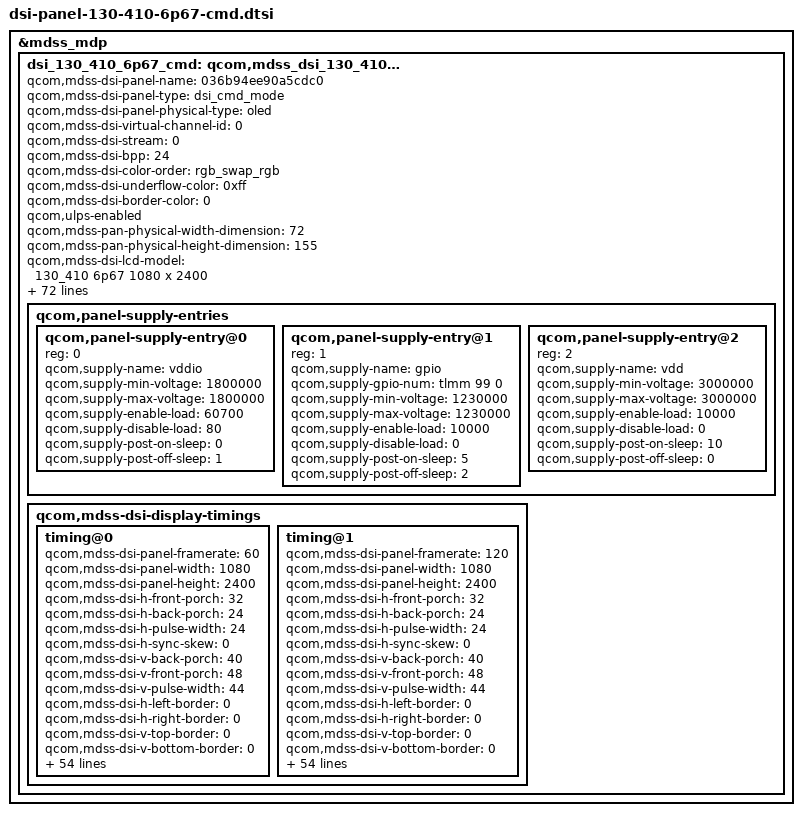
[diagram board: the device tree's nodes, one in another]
&mdss_mdp {
	dsi_130_410_6p67_cmd: qcom,mdss_dsi_130_410_6p67_cmd {
		qcom,mdss-dsi-panel-name = "036b94ee90a5cdc0";
		qcom,mdss-dsi-panel-type = "dsi_cmd_mode";
		qcom,mdss-dsi-panel-physical-type = "oled";
		qcom,mdss-dsi-virtual-channel-id = <0>;
		qcom,mdss-dsi-stream = <0>;
		qcom,mdss-dsi-bpp = <24>;
		qcom,mdss-dsi-color-order = "rgb_swap_rgb";
		qcom,mdss-dsi-underflow-color = <0xff>;
		qcom,mdss-dsi-border-color = <0>;
		qcom,ulps-enabled;
		qcom,mdss-pan-physical-width-dimension = <72>;
		qcom,mdss-pan-physical-height-dimension = <155>;
		qcom,mdss-dsi-lcd-model = "130_410 6p67 1080 x 2400";

		/* mipi dsi setting */
		qcom,dsi-ctrl-num = <0>;
		qcom,dsi-phy-num = <0>;
		qcom,dsi-sec-ctrl-num = <1>;
		qcom,dsi-sec-phy-num = <1>;
		qcom,mdss-dsi-traffic-mode = "non_burst_sync_event";
		qcom,mdss-dsi-lane-map = "lane_map_0123";
		qcom,mdss-dsi-bllp-eof-power-mode;
		qcom,mdss-dsi-bllp-power-mode;
		qcom,mdss-dsi-lane-0-state;
		qcom,mdss-dsi-lane-1-state;
		qcom,mdss-dsi-lane-2-state;
		qcom,mdss-dsi-lane-3-state;
		qcom,mdss-dsi-dma-trigger = "trigger_sw";
		qcom,mdss-dsi-mdp-trigger = "none";
		qcom,dsi-select-clocks = "mux_byte_clk0", "mux_pixel_clk0";
		qcom,dsi-select-sec-clocks = "mux_byte_clk1", "mux_pixel_clk1";

		/* TE setting */
		qcom,mdss-dsi-te-pin-select = <1>;
		qcom,mdss-dsi-wr-mem-start = <0x2c>;
		qcom,mdss-dsi-wr-mem-continue = <0x3c>;
		qcom,mdss-dsi-te-dcs-command = <1>;
		qcom,mdss-dsi-te-check-enable;
		qcom,mdss-dsi-te-using-te-pin;

		/* hdr setting */
		qcom,mdss-dsi-panel-hdr-enabled;
		qcom,mdss-dsi-panel-hdr-color-primaries = <14500 15500 32000
			17000 15500 30000 8000 3000>;
		qcom,mdss-dsi-panel-peak-brightness = <4200000>;
		qcom,mdss-dsi-panel-blackness-level = <3230>;

		/* hbm enable */
		qcom,mdss-dsi-panel-hbm-enabled;
		/* hbm delay threshold */
		qcom,mdss-dsi-hbm-left-delaythr = <10000>;
		qcom,mdss-dsi-hbm-right-delaythr = <11500>;

		/* gpio setting */
		qcom,dsi-panel-gpio-address = <0x0F100000 0x1000>;
		qcom,dsi-panel-gpio-pins = <44 99>;
		qcom,dsi-panel-gpio-names = "reset-gpio", "vdd-gpio";

		/* esd check setting */
		qcom,mdss-dsi-panel-status-check-mode = "reg_read";
		qcom,mdss-dsi-panel-status-command = [
			15 01 00 00 01 00 02 FE 00
			06 01 00 01 00 00 01 0A
		];
		qcom,mdss-dsi-panel-status-command-state = "dsi_lp_mode";
		qcom,mdss-dsi-panel-status-value = <0x00 0x9c>;
		qcom,mdss-dsi-panel-status-read-length = <1 1>;
		qcom,esd-check-enabled;

		/* pcd detect*/
		qcom,mdss-dsi-panel-lcd-check-pcd-support;
		qcom,mdss-dsi-panel-lcd-pcd_value_compare_mode = <0>;
		qcom,mdss-dsi-panel-lcd-pcd_mask = <0xff>;
		qcom,mdss-dsi-panel-lcd-pcd_det_num = <1>;
		qcom,mdss-dsi-panel-lcd-check-pcd-expect_vals = <0xFF>;

		/* check reg */
		qcom,mdss-dsi-panel-lcd-check-reg-enabled;
		qcom,mdss-dsi-panel-lcd-check-reg-expect_vals = <0x9c>;

		/* oem info */
		qcom,mdss-dsi-panel-oem-info-enabled;
		qcom,mdss-dsi-panel-oem-2d-barcode-enabled;
		qcom,mdss-dsi-panel-oem-sn-enabled;

		/* backlight setting */
		qcom,mdss-dsi-bl-pmic-control-type = "bl_ctrl_dcs";
		qcom,mdss-dsi-bl-min-level = <3>;
		qcom,mdss-dsi-bl-max-level = <4095>;
		qcom,mdss-brightness-max-level = <4095>;
		qcom,mdss-dsi-bl-inverted-dbv;
		qcom,mdss-dsi-bl-max-nit = <1000>;

		/* dfps setting */
		qcom,dsi-fps-list = <60 120>;

		/* skip normal backlight set when on aod lp1 scene */
		qcom,skip-normal-bl-set-on-aod-enabled;

		/* power on/off timing setting */
		qcom,platform-reset-gpio = <&tlmm 44 0>;
		qcom,mdss-dsi-reset-sequence = <1 1>, <0 1>, <1 50>;
		qcom,mdss-dsi-reset-pre-off-sleep = <2>;
		qcom,mdss-dsi-panel-reset-in-lp11;
		qcom,panel-supply-entries {
			qcom,panel-supply-entry@0 {
				reg = <0>;
				qcom,supply-name = "vddio";
				qcom,supply-min-voltage = <1800000>;
				qcom,supply-max-voltage = <1800000>;
				qcom,supply-enable-load = <60700>;
				qcom,supply-disable-load = <80>;
				qcom,supply-post-on-sleep = <0>;
				qcom,supply-post-off-sleep = <1>;
			};
			qcom,panel-supply-entry@1 {
				reg = <1>;
				qcom,supply-name = "gpio";
				qcom,supply-gpio-num = <&tlmm 99 0>;
				qcom,supply-min-voltage = <1230000>;
				qcom,supply-max-voltage = <1230000>;
				qcom,supply-enable-load = <10000>;
				qcom,supply-disable-load = <0>;
				qcom,supply-post-on-sleep = <5>;
				qcom,supply-post-off-sleep = <2>;
                        };
			qcom,panel-supply-entry@2 {
				reg = <2>;
				qcom,supply-name = "vdd";
				qcom,supply-min-voltage = <3000000>;
				qcom,supply-max-voltage = <3000000>;
				qcom,supply-enable-load = <10000>;
				qcom,supply-disable-load = <0>;
				qcom,supply-post-on-sleep = <10>;
				qcom,supply-post-off-sleep = <0>;
			};
		};
		/* display timing0 */
		qcom,mdss-dsi-display-timings {
			timing@0 {
				qcom,mdss-dsi-panel-framerate = <60>;
				qcom,mdss-dsi-panel-width = <1080>;
				qcom,mdss-dsi-panel-height = <2400>;
				qcom,mdss-dsi-h-front-porch = <32>;
				qcom,mdss-dsi-h-back-porch = <24>;
				qcom,mdss-dsi-h-pulse-width = <24>;
				qcom,mdss-dsi-h-sync-skew = <0>;
				qcom,mdss-dsi-v-back-porch = <40>;
				qcom,mdss-dsi-v-front-porch = <48>;
				qcom,mdss-dsi-v-pulse-width = <44>;
				qcom,mdss-dsi-h-left-border = <0>;
				qcom,mdss-dsi-h-right-border = <0>;
				qcom,mdss-dsi-v-top-border = <0>;
				qcom,mdss-dsi-v-bottom-border = <0>;
				qcom,mdss-dsi-panel-jitter = <0x4 0x1>;

				qcom,mdss-dsi-on-command = [
					15 01 00 00 00 00 02 FE D2
					15 01 00 00 00 00 02 4F 08
					15 01 00 00 00 00 02 50 12
					15 01 00 00 00 00 02 51 aB
					15 01 00 00 00 00 02 52 30
					15 01 00 00 00 00 02 53 09
					15 01 00 00 00 00 02 54 60
					15 01 00 00 00 00 02 55 04
					15 01 00 00 00 00 02 56 38
					15 01 00 00 00 00 02 58 00
					15 01 00 00 00 00 02 59 14
					15 01 00 00 00 00 02 5a 02
					15 01 00 00 00 00 02 5b 1c
					15 01 00 00 00 00 02 5c 02
					15 01 00 00 00 00 02 5d 00
					15 01 00 00 00 00 02 5e 20
					15 01 00 00 00 00 02 5f 01
					15 01 00 00 00 00 02 60 d5
					15 01 00 00 00 00 02 61 00
					15 01 00 00 00 00 02 62 07
					15 01 00 00 00 00 02 63 0d
					15 01 00 00 00 00 02 64 05
					15 01 00 00 00 00 02 65 7a
					15 01 00 00 00 00 02 66 05
					15 01 00 00 00 00 02 67 16
					15 01 00 00 00 00 02 68 18
					15 01 00 00 00 00 02 69 00
					15 01 00 00 00 00 02 6a 10
					15 01 00 00 00 00 02 6b f0
					15 01 00 00 00 00 02 6c 07
					15 01 00 00 00 00 02 6d 10
					15 01 00 00 00 00 02 6e 20
					15 01 00 00 00 00 02 6f 00
					15 01 00 00 00 00 02 70 06
					15 01 00 00 00 00 02 71 0f
					15 01 00 00 00 00 02 72 0f
					15 01 00 00 00 00 02 73 33
					15 01 00 00 00 00 02 74 0e
					15 01 00 00 00 00 02 75 1c
					15 01 00 00 00 00 02 76 2a
					15 01 00 00 00 00 02 77 38
					15 01 00 00 00 00 02 78 46
					15 01 00 00 00 00 02 79 54
					15 01 00 00 00 00 02 7a 62
					15 01 00 00 00 00 02 7b 69
					15 01 00 00 00 00 02 7c 70
					15 01 00 00 00 00 02 7d 77
					15 01 00 00 00 00 02 7e 79
					15 01 00 00 00 00 02 7f 7b
					15 01 00 00 00 00 02 80 7d
					15 01 00 00 00 00 02 81 7e
					15 01 00 00 00 00 02 82 02
					15 01 00 00 00 00 02 83 02
					15 01 00 00 00 00 02 84 22
					15 01 00 00 00 00 02 85 00
					15 01 00 00 00 00 02 86 2a
					15 01 00 00 00 00 02 87 40
					15 01 00 00 00 00 02 88 2a
					15 01 00 00 00 00 02 89 be
					15 01 00 00 00 00 02 8a 3a
					15 01 00 00 00 00 02 8b fc
					15 01 00 00 00 00 02 8c 3a
					15 01 00 00 00 00 02 8d fa
					15 01 00 00 00 00 02 8e 3a
					15 01 00 00 00 00 02 8f f8
					15 01 00 00 00 00 02 90 3b
					15 01 00 00 00 00 02 91 38
					15 01 00 00 00 00 02 92 3b
					15 01 00 00 00 00 02 93 78
					15 01 00 00 00 00 02 94 3b
					15 01 00 00 00 00 02 95 b6
					15 01 00 00 00 00 02 96 4b
					15 01 00 00 00 00 02 97 b6
					15 01 00 00 00 00 02 98 4b
					15 01 00 00 00 00 02 99 f4
					15 01 00 00 00 00 02 9a 4b
					15 01 00 00 00 00 02 9b f4
					15 01 00 00 00 00 02 9c 6c
					15 01 00 00 00 00 02 9d 34
					15 01 00 00 00 00 02 9e 84
					15 01 00 00 00 00 02 9f 74
					15 01 00 00 00 00 02 a2 02
					15 01 00 00 00 00 02 a3 1c
					15 01 00 00 00 00 02 a4 74
					15 01 00 00 00 00 02 a5 00
					15 01 00 00 00 00 02 a6 00
					15 01 00 00 00 00 02 a7 00
					15 01 00 00 00 00 02 a9 00
					15 01 00 00 00 00 02 aa 00
					15 01 00 00 00 00 02 a0 80
					15 01 00 00 00 00 02 FE 88
					15 01 00 00 00 00 02 19 91
					15 01 00 00 00 00 02 FE 26
					15 01 00 00 00 00 02 1D 29
					15 01 00 00 00 00 02 FE A0
					15 01 00 00 00 00 02 06 36
					15 01 00 00 00 00 02 FE B0
					15 01 00 00 00 00 02 16 77
					15 01 00 00 00 00 02 17 77
					15 01 00 00 00 00 02 FE 40
					15 01 00 00 00 00 02 84 12
					15 01 00 00 00 00 02 FE 00
					15 01 00 00 00 00 02 02 00
					15 01 00 00 00 00 02 fe b0
					15 01 00 00 00 00 02 91 70
					15 01 00 00 00 00 02 27 7e
					15 01 00 00 00 00 02 FE 38
					15 01 00 00 00 00 02 17 0F
					15 01 00 00 00 00 02 18 0F
					15 01 00 00 00 00 02 FE 00
					15 01 00 00 00 00 02 fa 01
					15 01 00 00 00 00 02 C2 08
					15 01 00 00 00 00 02 35 00
					15 01 00 00 00 00 02 FE 00
					05 01 00 00 64 00 01 11
					05 01 00 00 14 00 01 29
				];

				qcom,mdss-dsi-off-command = [
					05 01 00 00 46 00 01 28
					05 01 00 00 78 00 01 10
				];

				qcom,mdss-dsi-fp-hbm-enable-commands = [
					39 01 00 00 00 00 03 51 0F FF
				];

				//qcom,mdss-dsi-batchinfo-read-commands = [
				//	39 01 00 00 00 00 06 F0 55 AA 52 08 01
				//	06 01 00 01 00 00 01 DC
				//];

				//qcom,mdss-dsi-lhbm-enable-commands = [
				//	15 00 00 00 00 00 02 2F 02
				//	05 01 00 00 00 00 01 85
				//];

				//qcom,mdss-dsi-lhbm-disable-commands = [
				//	05 00 00 00 00 00 01 86
				//	15 01 00 00 00 00 02 2F 01
				//];

				qcom,mdss-dsi-timing-switch-command = [
					15 01 00 00 01 00 02 FE 00
					15 01 00 00 11 00 02 02 00
				];

				qcom,mdss-dsi-lp1-command = [
					15 01 00 00 00 00 02 FE 00
					05 01 00 00 00 00 01 39
					15 01 00 00 00 00 02 FE 40
					15 01 00 00 00 00 02 15 41
					15 01 00 00 00 00 02 B2 43
					15 01 00 00 09 00 02 FE 00
				];

				qcom,mdss-dsi-nolp-command = [
					15 01 00 00 00 00 02 FE 40
					15 01 00 00 00 00 02 15 49
					15 01 00 00 00 00 02 B2 4E
					15 01 00 00 00 00 02 FE 00
					39 01 00 00 00 00 03 51 00 00
					05 01 00 00 00 00 01 38
				];

				qcom,mdss-dsi-alpm-low-light-commands = [
					15 01 00 00 00 00 02 FE 00
					39 01 00 00 00 00 03 51 01 55
				];

				qcom,mdss-dsi-alpm-middle-light-commands = [
					15 01 00 00 00 00 02 FE 00
					39 01 00 00 00 00 03 51 07 FF
				];

				qcom,mdss-dsi-alpm-high-light-commands = [
					15 01 00 00 00 00 02 FE 00
					39 01 00 00 00 00 03 51 0F FE
				];

				qcom,mdss-dsi-panel-lcd-check-reg-commands = [
					15 01 00 00 00 00 02 FE 00
					06 01 00 01 00 00 01 0A
				];

				qcom,mdss-dsi-oeminfo-read-commands = [
					15 01 00 00 00 00 02 FE C2
					06 01 00 01 00 00 01 00
					06 01 00 01 00 00 01 01
					06 01 00 01 00 00 01 02
					06 01 00 01 00 00 01 03
					06 01 00 01 00 00 01 04
					06 01 00 01 00 00 01 05
					06 01 00 01 00 00 01 06
					06 01 00 01 00 00 01 07
					06 01 00 01 00 00 01 08
					06 01 00 01 00 00 01 09
					06 01 00 01 00 00 01 0A
					06 01 00 01 00 00 01 0B
					06 01 00 01 00 00 01 0C
					06 01 00 01 00 00 01 0D
					06 01 00 01 00 00 01 0E
					06 01 00 01 00 00 01 0F
					06 01 00 01 00 00 01 10
					06 01 00 01 00 00 01 11
					06 01 00 01 00 00 01 12
					06 01 00 01 00 00 01 13
					06 01 00 01 00 00 01 14
					15 01 00 00 00 00 02 FE 00
				];

				qcom,mdss-dsi-lcd-pcd-check-open-commands = [
					15 01 00 00 00 00 02 FE 40
					15 01 00 00 00 00 02 5D 28
					15 01 00 00 00 00 02 51 05
					15 01 00 00 00 00 02 FE 00
				];

				qcom,mdss-dsi-lcd-pcd-check-reg-commands = [
					15 01 00 00 00 00 02 FE 40
					06 01 00 01 00 00 01 DB
					15 01 00 00 00 00 02 FE 00
				];

				qcom,mdss-dsi-lcd-pcd-check-close-commands = [
					15 01 00 00 00 00 02 FE 40
					15 01 00 00 00 00 02 5D 08
					15 01 00 00 00 00 02 51 00
					15 01 00 00 00 00 02 FE 00
				];

				qcom,mdss-dsi-on-command-state = "dsi_lp_mode";
				qcom,mdss-dsi-off-command-state = "dsi_hs_mode";
				qcom,mdss-dsi-panel-lcd-check-reg-commands-state =
					"dsi_lp_mode";
				qcom,mdss-dsi-oeminfo-read-commands-state =
					"dsi_lp_mode";
				qcom,mdss-dsi-lcd-pcd-check-open-commands-state =
					"dsi_lp_mode";
				qcom,mdss-dsi-lcd-pcd-check-reg-commands-state =
					"dsi_lp_mode";
				qcom,mdss-dsi-lcd-pcd-check-close-commands-state =
					"dsi_lp_mode";

				qcom,mdss-dsi-h-sync-pulse = <0>;
				qcom,compression-mode = "dsc";
				qcom,mdss-dsc-version = <0x12>;
				qcom,mdss-dsc-slice-height = <20>;
				qcom,mdss-dsc-slice-width = <540>;
				qcom,mdss-dsc-slice-per-pkt = <2>;
				qcom,mdss-dsc-bit-per-component = <10>;
				qcom,mdss-dsc-bit-per-pixel = <8>;
				qcom,mdss-dsc-block-prediction-enable;
				qcom,mdss-dsi-panel-phy-timings = [00 10 04 04 12 1E 04
						04 04 03 02 04 0E 09];
				qcom,display-topology = <1 1 1>;
				qcom,default-topology-index = <0>;
			};
			timing@1 {
				qcom,mdss-dsi-panel-framerate = <120>;
				qcom,mdss-dsi-panel-width = <1080>;
				qcom,mdss-dsi-panel-height = <2400>;
				qcom,mdss-dsi-h-front-porch = <32>;
				qcom,mdss-dsi-h-back-porch = <24>;
				qcom,mdss-dsi-h-pulse-width = <24>;
				qcom,mdss-dsi-h-sync-skew = <0>;
				qcom,mdss-dsi-v-back-porch = <40>;
				qcom,mdss-dsi-v-front-porch = <48>;
				qcom,mdss-dsi-v-pulse-width = <44>;
				qcom,mdss-dsi-h-left-border = <0>;
				qcom,mdss-dsi-h-right-border = <0>;
				qcom,mdss-dsi-v-top-border = <0>;
				qcom,mdss-dsi-v-bottom-border = <0>;
				qcom,mdss-dsi-panel-jitter = <0x4 0x1>;

				qcom,mdss-dsi-on-command = [
					15 01 00 00 00 00 02 FE D2
					15 01 00 00 00 00 02 4F 08
					15 01 00 00 00 00 02 50 12
					15 01 00 00 00 00 02 51 aB
					15 01 00 00 00 00 02 52 30
					15 01 00 00 00 00 02 53 09
					15 01 00 00 00 00 02 54 60
					15 01 00 00 00 00 02 55 04
					15 01 00 00 00 00 02 56 38
					15 01 00 00 00 00 02 58 00
					15 01 00 00 00 00 02 59 14
					15 01 00 00 00 00 02 5a 02
					15 01 00 00 00 00 02 5b 1c
					15 01 00 00 00 00 02 5c 02
					15 01 00 00 00 00 02 5d 00
					15 01 00 00 00 00 02 5e 20
					15 01 00 00 00 00 02 5f 01
					15 01 00 00 00 00 02 60 d5
					15 01 00 00 00 00 02 61 00
					15 01 00 00 00 00 02 62 07
					15 01 00 00 00 00 02 63 0D
					15 01 00 00 00 00 02 64 05
					15 01 00 00 00 00 02 65 7A
					15 01 00 00 00 00 02 66 05
					15 01 00 00 00 00 02 67 16
					15 01 00 00 00 00 02 68 18
					15 01 00 00 00 00 02 69 00
					15 01 00 00 00 00 02 6a 10
					15 01 00 00 00 00 02 6b f0
					15 01 00 00 00 00 02 6c 07
					15 01 00 00 00 00 02 6d 10
					15 01 00 00 00 00 02 6e 20
					15 01 00 00 00 00 02 6f 00
					15 01 00 00 00 00 02 70 06
					15 01 00 00 00 00 02 71 0f
					15 01 00 00 00 00 02 72 0f
					15 01 00 00 00 00 02 73 33
					15 01 00 00 00 00 02 74 0e
					15 01 00 00 00 00 02 75 1c
					15 01 00 00 00 00 02 76 2a
					15 01 00 00 00 00 02 77 38
					15 01 00 00 00 00 02 78 46
					15 01 00 00 00 00 02 79 54
					15 01 00 00 00 00 02 7a 62
					15 01 00 00 00 00 02 7b 69
					15 01 00 00 00 00 02 7c 70
					15 01 00 00 00 00 02 7d 77
					15 01 00 00 00 00 02 7e 79
					15 01 00 00 00 00 02 7f 7b
					15 01 00 00 00 00 02 80 7d
					15 01 00 00 00 00 02 81 7e
					15 01 00 00 00 00 02 82 02
					15 01 00 00 00 00 02 83 02
					15 01 00 00 00 00 02 84 22
					15 01 00 00 00 00 02 85 00
					15 01 00 00 00 00 02 86 2a
					15 01 00 00 00 00 02 87 40
					15 01 00 00 00 00 02 88 2a
					15 01 00 00 00 00 02 89 be
					15 01 00 00 00 00 02 8a 3a
					15 01 00 00 00 00 02 8b fc
					15 01 00 00 00 00 02 8c 3a
					15 01 00 00 00 00 02 8d fa
					15 01 00 00 00 00 02 8e 3a
					15 01 00 00 00 00 02 8f f8
					15 01 00 00 00 00 02 90 3b
					15 01 00 00 00 00 02 91 38
					15 01 00 00 00 00 02 92 3b
					15 01 00 00 00 00 02 93 78
					15 01 00 00 00 00 02 94 3b
					15 01 00 00 00 00 02 95 b6
					15 01 00 00 00 00 02 96 4b
					15 01 00 00 00 00 02 97 B6
					15 01 00 00 00 00 02 98 4B
					15 01 00 00 00 00 02 99 F4
					15 01 00 00 00 00 02 9a 4B
					15 01 00 00 00 00 02 9b F4
					15 01 00 00 00 00 02 9c 6C
					15 01 00 00 00 00 02 9d 34
					15 01 00 00 00 00 02 9e 84
					15 01 00 00 00 00 02 9f 74
					15 01 00 00 00 00 02 a2 02
					15 01 00 00 00 00 02 a3 1c
					15 01 00 00 00 00 02 a4 74
					15 01 00 00 00 00 02 a5 00
					15 01 00 00 00 00 02 a6 00
					15 01 00 00 00 00 02 a7 00
					15 01 00 00 00 00 02 a9 00
					15 01 00 00 00 00 02 aa 00
					15 01 00 00 00 00 02 a0 80
					15 01 00 00 00 00 02 FE 88
					15 01 00 00 00 00 02 19 91
					15 01 00 00 00 00 02 FE 26
					15 01 00 00 00 00 02 1D 29
					15 01 00 00 00 00 02 FE A0
					15 01 00 00 00 00 02 06 36
					15 01 00 00 00 00 02 FE B0
					15 01 00 00 00 00 02 16 77
					15 01 00 00 00 00 02 17 77
					15 01 00 00 00 00 02 FE 40
					15 01 00 00 00 00 02 84 12
					15 01 00 00 00 00 02 FE 00
					15 01 00 00 00 00 02 02 05
					15 01 00 00 00 00 02 fe b0
					15 01 00 00 00 00 02 91 70
					15 01 00 00 00 00 02 27 7e
					15 01 00 00 00 00 02 FE 38
					15 01 00 00 00 00 02 17 0F
					15 01 00 00 00 00 02 18 0F
					15 01 00 00 00 00 02 FE 00
					15 01 00 00 00 00 02 fa 01
					15 01 00 00 00 00 02 C2 08
					15 01 00 00 00 00 02 35 00
					15 01 00 00 00 00 02 FE 00
					05 01 00 00 64 00 01 11
					05 01 00 00 14 00 01 29
				];

				qcom,mdss-dsi-off-command = [
					05 01 00 00 46 00 01 28
					05 01 00 00 78 00 01 10
				];

				qcom,mdss-dsi-fp-hbm-enable-commands = [
					39 01 00 00 00 00 03 51 0F FF
				];

				//qcom,mdss-dsi-batchinfo-read-commands = [
				//	39 01 00 00 00 00 06 F0 55 AA 52 08 01
				//	06 01 00 01 00 00 01 DC
				//];

				//qcom,mdss-dsi-lhbm-enable-commands = [
				//	15 00 00 00 00 00 02 2F 02
				//	05 01 00 00 00 00 01 85
				//];

				//qcom,mdss-dsi-lhbm-disable-commands = [
				//	05 00 00 00 00 00 01 86
				//	15 01 00 00 00 00 02 2F 01
				//];

				qcom,mdss-dsi-timing-switch-command = [
					15 01 00 00 01 00 02 FE 00
					15 01 00 00 09 00 02 02 05
				];

				qcom,mdss-dsi-lp1-command = [
					15 01 00 00 00 00 02 FE 00
					15 01 00 00 2C 00 02 02 00
					05 01 00 00 00 00 01 39
					15 01 00 00 00 00 02 FE 40
					15 01 00 00 00 00 02 15 41
					15 01 00 00 00 00 02 B2 43
					15 01 00 00 09 00 02 FE 00
				];

				qcom,mdss-dsi-nolp-command = [
					15 01 00 00 00 00 02 FE 40
					15 01 00 00 00 00 02 15 49
					15 01 00 00 00 00 02 B2 4E
					15 01 00 00 00 00 02 FE 00
					39 01 00 00 00 00 03 51 00 00
					05 01 00 00 00 00 01 38
				];

				qcom,mdss-dsi-alpm-low-light-commands = [
					15 01 00 00 00 00 02 FE 00
					39 01 00 00 00 00 03 51 01 55
				];

				qcom,mdss-dsi-alpm-middle-light-commands = [
					15 01 00 00 00 00 02 FE 00
					39 01 00 00 00 00 03 51 07 FF
				];

				qcom,mdss-dsi-alpm-high-light-commands = [
					15 01 00 00 00 00 02 FE 00
					39 01 00 00 00 00 03 51 0F FE
				];

				qcom,mdss-dsi-panel-lcd-check-reg-commands = [
					15 01 00 00 00 00 02 FE 00
					06 01 00 01 00 00 01 0A
				];

				qcom,mdss-dsi-oeminfo-read-commands = [
					15 01 00 00 00 00 02 FE C2
					06 01 00 01 00 00 01 00
					06 01 00 01 00 00 01 01
					06 01 00 01 00 00 01 02
					06 01 00 01 00 00 01 03
					06 01 00 01 00 00 01 04
					06 01 00 01 00 00 01 05
					06 01 00 01 00 00 01 06
					06 01 00 01 00 00 01 07
					06 01 00 01 00 00 01 08
					06 01 00 01 00 00 01 09
					06 01 00 01 00 00 01 0A
					06 01 00 01 00 00 01 0B
					06 01 00 01 00 00 01 0C
					06 01 00 01 00 00 01 0D
					06 01 00 01 00 00 01 0E
					06 01 00 01 00 00 01 0F
					06 01 00 01 00 00 01 10
					06 01 00 01 00 00 01 11
					06 01 00 01 00 00 01 12
					06 01 00 01 00 00 01 13
					06 01 00 01 00 00 01 14
					15 01 00 00 00 00 02 FE 00
				];

				qcom,mdss-dsi-lcd-pcd-check-open-commands = [
					15 01 00 00 00 00 02 FE 40
					15 01 00 00 00 00 02 5D 28
					15 01 00 00 00 00 02 51 05
					15 01 00 00 00 00 02 FE 00
				];

				qcom,mdss-dsi-lcd-pcd-check-reg-commands = [
					15 01 00 00 00 00 02 FE 40
					06 01 00 01 00 00 01 DB
					15 01 00 00 00 00 02 FE 00
				];

				qcom,mdss-dsi-lcd-pcd-check-close-commands = [
					15 01 00 00 00 00 02 FE 40
					15 01 00 00 00 00 02 5D 08
					15 01 00 00 00 00 02 51 00
					15 01 00 00 00 00 02 FE 00
				];

				qcom,mdss-dsi-on-command-state = "dsi_lp_mode";
				qcom,mdss-dsi-off-command-state = "dsi_hs_mode";
				qcom,mdss-dsi-panel-lcd-check-reg-commands-state =
					"dsi_lp_mode";
				qcom,mdss-dsi-oeminfo-read-commands-state =
					"dsi_lp_mode";
				qcom,mdss-dsi-lcd-pcd-check-open-commands-state =
					"dsi_lp_mode";
				qcom,mdss-dsi-lcd-pcd-check-reg-commands-state =
					"dsi_lp_mode";
				qcom,mdss-dsi-lcd-pcd-check-close-commands-state =
					"dsi_lp_mode";

				qcom,mdss-dsi-h-sync-pulse = <0>;
				qcom,compression-mode = "dsc";
				qcom,mdss-dsc-version = <0x12>;
				qcom,mdss-dsc-slice-height = <20>;
				qcom,mdss-dsc-slice-width = <540>;
				qcom,mdss-dsc-slice-per-pkt = <2>;
				qcom,mdss-dsc-bit-per-component = <10>;
				qcom,mdss-dsc-bit-per-pixel = <8>;
				qcom,mdss-dsc-block-prediction-enable;
				qcom,mdss-dsi-panel-phy-timings = [00 1C 08 07 17 16 07
					07 07 08 02 04 19 0C];
				qcom,display-topology = <1 1 1>;
				qcom,default-topology-index = <0>;
			};
		};
	};
};
